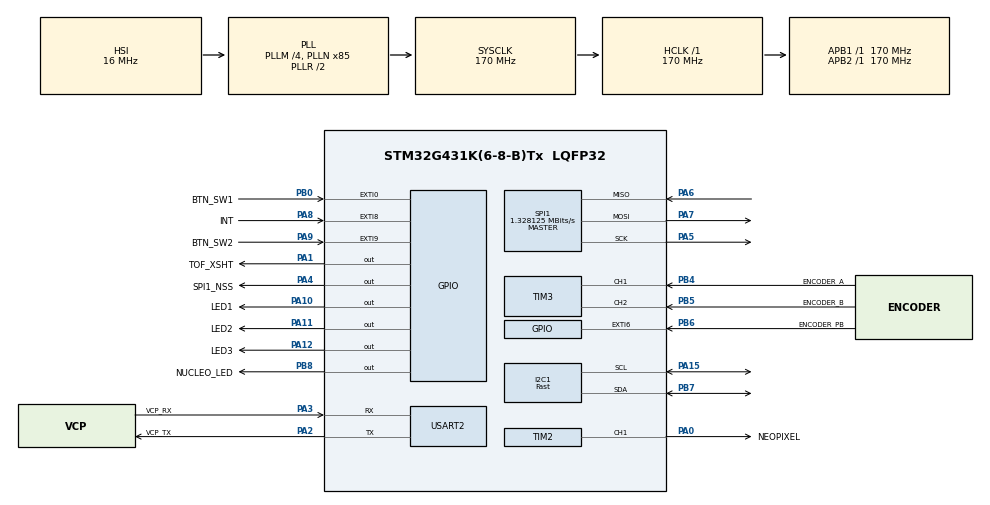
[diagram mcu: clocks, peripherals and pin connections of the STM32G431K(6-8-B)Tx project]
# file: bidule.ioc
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Dma.I2C1_TX.1.Direction=DMA_MEMORY_TO_PERIPH
Dma.I2C1_TX.1.EventEnable=DISABLE
Dma.I2C1_TX.1.Instance=DMA1_Channel2
Dma.I2C1_TX.1.MemDataAlignment=DMA_MDATAALIGN_BYTE
Dma.I2C1_TX.1.MemInc=DMA_MINC_ENABLE
Dma.I2C1_TX.1.Mode=DMA_NORMAL
Dma.I2C1_TX.1.PeriphDataAlignment=DMA_PDATAALIGN_BYTE
Dma.I2C1_TX.1.PeriphInc=DMA_PINC_DISABLE
Dma.I2C1_TX.1.Polarity=HAL_DMAMUX_REQ_GEN_RISING
Dma.I2C1_TX.1.Priority=DMA_PRIORITY_LOW
Dma.I2C1_TX.1.RequestNumber=1
Dma.I2C1_TX.1.SignalID=NONE
Dma.I2C1_TX.1.SyncEnable=DISABLE
Dma.I2C1_TX.1.SyncPolarity=HAL_DMAMUX_SYNC_NO_EVENT
Dma.I2C1_TX.1.SyncRequestNumber=1
Dma.I2C1_TX.1.SyncSignalID=NONE
Dma.Request0=TIM2_CH1
Dma.Request1=I2C1_TX
Dma.TIM2_CH1.0.Direction=DMA_MEMORY_TO_PERIPH
Dma.TIM2_CH1.0.EventEnable=DISABLE
Dma.TIM2_CH1.0.Instance=DMA1_Channel1
Dma.TIM2_CH1.0.MemDataAlignment=DMA_MDATAALIGN_BYTE
Dma.TIM2_CH1.0.MemInc=DMA_MINC_ENABLE
Dma.TIM2_CH1.0.Mode=DMA_CIRCULAR
Dma.TIM2_CH1.0.PeriphDataAlignment=DMA_PDATAALIGN_WORD
Dma.TIM2_CH1.0.PeriphInc=DMA_PINC_DISABLE
Dma.TIM2_CH1.0.Polarity=HAL_DMAMUX_REQ_GEN_RISING
Dma.TIM2_CH1.0.Priority=DMA_PRIORITY_LOW
Dma.TIM2_CH1.0.RequestNumber=1
Dma.TIM2_CH1.0.SignalID=NONE
Dma.TIM2_CH1.0.SyncEnable=DISABLE
Dma.TIM2_CH1.0.SyncPolarity=HAL_DMAMUX_SYNC_NO_EVENT
Dma.TIM2_CH1.0.SyncRequestNumber=1
Dma.TIM2_CH1.0.SyncSignalID=NONE
FREERTOS.Tasks01=defaultTask,0,128,StartDefaultTask,Default,NULL,Dynamic,NULL,NULL
FREERTOS.configTOTAL_HEAP_SIZE=6144
I2C1.I2C_Speed_Mode=I2C_Fast
I2C1.Timing=0x40621236
Mcu.Family=STM32G4
Mcu.Name=STM32G431K(6-8-B)Tx
Mcu.Package=LQFP32
NVIC.DMA1_Channel1_IRQn=true\:5\:0\:false\:false\:true\:true\:false\:true\:true
NVIC.DMA1_Channel2_IRQn=true\:5\:0\:false\:false\:true\:true\:false\:true\:true
NVIC.EXTI0_IRQn=true\:5\:0\:false\:false\:true\:true\:true\:true\:true
NVIC.EXTI9_5_IRQn=true\:5\:0\:false\:false\:true\:true\:true\:true\:true
NVIC.I2C1_ER_IRQn=true\:5\:0\:false\:false\:true\:true\:true\:true\:true
NVIC.I2C1_EV_IRQn=true\:5\:0\:false\:false\:true\:true\:true\:true\:true
NVIC.PriorityGroup=NVIC_PRIORITYGROUP_4
NVIC.TIM2_IRQn=true\:5\:0\:false\:false\:true\:true\:true\:true\:true
NVIC.TIM6_DAC_IRQn=true\:4\:0\:false\:false\:true\:false\:false\:true\:true
NVIC.TimeBase=TIM6_DAC_IRQn
NVIC.TimeBaseIP=TIM6
PA0.GPIO_Label=NEOPIXEL
PA0.Signal=S_TIM2_CH1
PA1.GPIO_Label=TOF_XSHT
PA1.Signal=GPIO_Output
PA10.GPIO_Label=LED1
PA10.Signal=GPIO_Output
PA11.GPIO_Label=LED2
PA11.Signal=GPIO_Output
PA12.GPIO_Label=LED3
PA12.Signal=GPIO_Output
PA13.GPIO_Label=T_SWDIO
PA13.Mode=Trace_Asynchronous_SW
PA13.Signal=SYS_JTMS-SWDIO
PA14.GPIO_Label=T_SWCLK
PA14.Mode=Trace_Asynchronous_SW
PA14.Signal=SYS_JTCK-SWCLK
PA15.GPIO_Pu=GPIO_PULLUP
PA15.Mode=I2C
PA15.Signal=I2C1_SCL
PA2.GPIO_Label=VCP_TX
PA2.Mode=Asynchronous
PA2.Signal=USART2_TX
PA3.GPIO_Label=VCP_RX
PA3.Mode=Asynchronous
PA3.Signal=USART2_RX
PA4.GPIO_Label=SPI1_NSS
PA4.PinState=GPIO_PIN_SET
PA4.Signal=GPIO_Output
PA5.GPIO_Speed=GPIO_SPEED_FREQ_LOW
PA5.Mode=Full_Duplex_Master
PA5.Signal=SPI1_SCK
PA6.GPIO_Speed=GPIO_SPEED_FREQ_LOW
PA6.Mode=Full_Duplex_Master
PA6.Signal=SPI1_MISO
PA7.GPIO_Speed=GPIO_SPEED_FREQ_LOW
PA7.Mode=Full_Duplex_Master
PA7.Signal=SPI1_MOSI
PA8.GPIO_Label=INT
PA8.Signal=GPXTI8
PA9.GPIO_Label=BTN_SW2
PA9.GPIO_ModeDefaultEXTI=GPIO_MODE_IT_FALLING
PA9.GPIO_PuPd=GPIO_PULLUP
PA9.Signal=GPXTI9
PB0.GPIO_Label=BTN_SW1
PB0.GPIO_ModeDefaultEXTI=GPIO_MODE_IT_FALLING
PB0.GPIO_PuPd=GPIO_PULLUP
PB0.Signal=GPXTI0
PB3.GPIO_Label=T_SWO
PB3.Mode=Trace_Asynchronous_SW
PB3.Signal=SYS_JTDO-SWO
PB4.GPIO_Label=ENCODER_A
PB4.GPIO_PuPd=GPIO_PULLUP
PB4.Signal=S_TIM3_CH1
PB5.GPIO_Label=ENCODER_B
PB5.GPIO_PuPd=GPIO_PULLUP
PB5.Signal=S_TIM3_CH2
PB6.GPIO_Label=ENCODER_PB
PB6.GPIO_PuPd=GPIO_PULLUP
PB6.Signal=GPXTI6
PB7.GPIO_Pu=GPIO_PULLUP
PB7.Mode=I2C
PB7.Signal=I2C1_SDA
PB8-BOOT0.GPIO_Label=NUCLEO_LED
PB8-BOOT0.Signal=GPIO_Output
ProjectManager.HeapSize=0x200
ProjectManager.StackSize=0x400
ProjectManager.TargetToolchain=CMake
RCC.ADC12Freq_Value=170000000
RCC.AHBFreq_Value=170000000
RCC.APB1Freq_Value=170000000
RCC.APB1TimFreq_Value=170000000
RCC.APB2Freq_Value=170000000
RCC.APB2TimFreq_Value=170000000
RCC.CortexFreq_Value=170000000
RCC.EXTERNAL_CLOCK_VALUE=12288000
RCC.HCLKFreq_Value=170000000
RCC.HSE_VALUE=8000000
RCC.HSI48_VALUE=48000000
RCC.HSI_VALUE=16000000
RCC.LSE_VALUE=32768
RCC.PLLM=RCC_PLLM_DIV4
RCC.PLLN=85
RCC.SYSCLKFreq_VALUE=170000000
RCC.SYSCLKSource=RCC_SYSCLKSOURCE_PLLCLK
RCC.USBFreq_Value=170000000
RCC.VCOOutputFreq_Value=340000000
SH.S_TIM2_CH1.0=TIM2_CH1,PWM Generation1 CH1
SH.S_TIM3_CH1.0=TIM3_CH1,Encoder_Interface
SH.S_TIM3_CH2.0=TIM3_CH2,Encoder_Interface
SPI1.BaudRatePrescaler=SPI_BAUDRATEPRESCALER_128
SPI1.CLKPhase=SPI_PHASE_2EDGE
SPI1.CLKPolarity=SPI_POLARITY_HIGH
SPI1.CalculateBaudRate=1.328125 MBits/s
SPI1.DataSize=SPI_DATASIZE_8BIT
SPI1.Direction=SPI_DIRECTION_2LINES
SPI1.Mode=SPI_MODE_MASTER
SPI1.VirtualType=VM_MASTER
TIM2.Channel-PWM\ Generation1\ CH1=TIM_CHANNEL_1
TIM2.PeriodNoDither=212
USART2.VirtualMode-Asynchronous=VM_ASYNC
VP_FREERTOS_VS_CMSIS_V1.Mode=CMSIS_V1
VP_SYS_VS_DBSignals.Mode=DisableDeadBatterySignals
VP_SYS_VS_tim6.Mode=TIM6
board=NUCLEO-G431KB

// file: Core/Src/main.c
/* USER CODE BEGIN Header */
/**
 ******************************************************************************
 * @file           : main.c
 * @brief          : Main program body
 ******************************************************************************
 * @attention
 *
 * Copyright (c) 2026 STMicroelectronics.
 * All rights reserved.
 *
 * This software is licensed under terms that can be found in the LICENSE file
 * in the root directory of this software component.
 * If no LICENSE file comes with this software, it is provided AS-IS.
 *
 ******************************************************************************
 */
/* USER CODE END Header */
#include "main.h"
#include "cmsis_os.h"
#include "dma.h"
#include "i2c.h"
#include "spi.h"
#include "tim.h"
#include "usart.h"
#include "gpio.h"

/* USER CODE BEGIN Includes */
#include <stdio.h>
#include <stdbool.h>
#include "bsp.h"
#include "app.h"
/* USER CODE END Includes */

/* USER CODE BEGIN PM */
#define LED_BLINK_PERIOD 250
/* USER CODE END PM */

void SystemClock_Config(void);
void MX_FREERTOS_Init(void);

/* USER CODE BEGIN 0 */
int _write(int file, char *ptr, int len) {
	HAL_UART_Transmit(&huart2, (uint8_t *)ptr, len, HAL_MAX_DELAY);
	return len;
}
/* USER CODE END 0 */

int main(void)
{

	/* MCU Configuration--------------------------------------------------------*/

	/* Reset of all peripherals, Initializes the Flash interface and the Systick. */
	HAL_Init();

	/* Configure the system clock */
	SystemClock_Config();

	/* Initialize all configured peripherals */
	MX_GPIO_Init();
	MX_DMA_Init();
	MX_I2C1_Init();
	MX_TIM3_Init();
	MX_TIM2_Init();
	MX_USART2_UART_Init();
	MX_SPI1_Init();
	/* USER CODE BEGIN 2 */
	printf("\r\n===== TD3 RTOS =====\r\n");

	/* Chaque module crée sa propre tâche. Le main choisit les priorités :
	 * l'ordonnancement global se lit ici, en un seul endroit. */
	bsp_init(3);			/* entrées : courte, bloque souvent : la plus prioritaire */
	bsp_init_display(1);	/* affichage : long, peu urgent (avant app_init) */
	app_init(2);			/* objet actif : crée sa file et sa tâche */

	printf("... All tasks are created\r\n");

	vTaskStartScheduler();
	/* USER CODE END 2 */

	/* Call init function for freertos objects (in cmsis_os2.c) */
	MX_FREERTOS_Init();

	/* Start scheduler */
	osKernelStart();

	/* We should never get here as control is now taken by the scheduler */

	/* Infinite loop */
	while (1) {

	}
}

void SystemClock_Config(void)
{
	RCC_OscInitTypeDef RCC_OscInitStruct = {0};
	RCC_ClkInitTypeDef RCC_ClkInitStruct = {0};

	/** Configure the main internal regulator output voltage
	 */
	HAL_PWREx_ControlVoltageScaling(PWR_REGULATOR_VOLTAGE_SCALE1_BOOST);

	/** Initializes the RCC Oscillators according to the specified parameters
	 * in the RCC_OscInitTypeDef structure.
	 */
	RCC_OscInitStruct.OscillatorType = RCC_OSCILLATORTYPE_HSI;
	RCC_OscInitStruct.HSIState = RCC_HSI_ON;
	RCC_OscInitStruct.HSICalibrationValue = RCC_HSICALIBRATION_DEFAULT;
	RCC_OscInitStruct.PLL.PLLState = RCC_PLL_ON;
	RCC_OscInitStruct.PLL.PLLSource = RCC_PLLSOURCE_HSI;
	RCC_OscInitStruct.PLL.PLLM = RCC_PLLM_DIV4;
	RCC_OscInitStruct.PLL.PLLN = 85;
	RCC_OscInitStruct.PLL.PLLP = RCC_PLLP_DIV2;
	RCC_OscInitStruct.PLL.PLLQ = RCC_PLLQ_DIV2;
	RCC_OscInitStruct.PLL.PLLR = RCC_PLLR_DIV2;
	if (HAL_RCC_OscConfig(&RCC_OscInitStruct) != HAL_OK)
	{
		Error_Handler();
	}

	/** Initializes the CPU, AHB and APB buses clocks
	 */
	RCC_ClkInitStruct.ClockType = RCC_CLOCKTYPE_HCLK|RCC_CLOCKTYPE_SYSCLK
			|RCC_CLOCKTYPE_PCLK1|RCC_CLOCKTYPE_PCLK2;
	RCC_ClkInitStruct.SYSCLKSource = RCC_SYSCLKSOURCE_PLLCLK;
	RCC_ClkInitStruct.AHBCLKDivider = RCC_SYSCLK_DIV1;
	RCC_ClkInitStruct.APB1CLKDivider = RCC_HCLK_DIV1;
	RCC_ClkInitStruct.APB2CLKDivider = RCC_HCLK_DIV1;

	if (HAL_RCC_ClockConfig(&RCC_ClkInitStruct, FLASH_LATENCY_4) != HAL_OK)
	{
		Error_Handler();
	}
}

void HAL_TIM_PeriodElapsedCallback(TIM_HandleTypeDef *htim)
{
	if (htim->Instance == TIM6)
	{
		HAL_IncTick();
	}
}

void Error_Handler(void)
{
	__disable_irq();
	while (1)
	{
	}
}
